# STM32G484xx register map
File version: 1.0
Registers are 32-bit, read-write, reset 0x0 unless marked. A register's access mark holds for its fields unless they carry their own. Offsets are from the block's base; [hi:lo] are bit positions.

## DAC — Digital to Analog Converter
Base 0x50000800
Same registers: DAC1 0x50000800 (alternate view of DAC), DAC2 0x50000C00, DAC3 0x50001000, DAC4 0x50001400
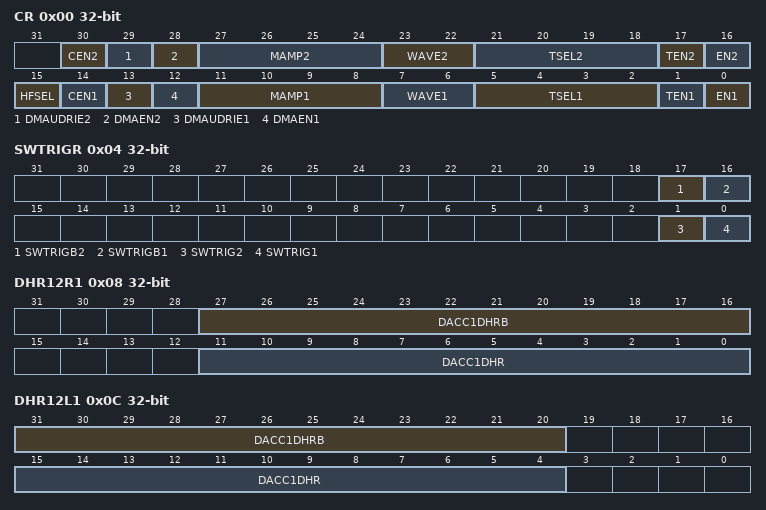
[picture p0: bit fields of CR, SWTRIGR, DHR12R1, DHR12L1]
0x00 CR — DAC control register
  [30] CEN2 — DAC channel2 calibration enable >
  [29] DMAUDRIE2 — DAC channel2 DMA underrun interrupt enable >
  [28] DMAEN2 — DAC channel2 DMA enabled
  [27:24] MAMP2 — MAMP2[3:0] (DAC channel2 Mask/Amplitude selector)
  [23:22] WAVE2 — WAVE2[1:0] (DAC channel2 noise/triangle wave generation enable)
  [21:18] TSEL2 — TSEL2[3:0] (DAC channel2 Trigger selection)
  [17] TEN2 — DAC channel2 Trigger enable
  [16] EN2 — DAC channel2 enable
  [15] HFSEL — DAC channel 1 and 2 high frequency mode enable >
  [14] CEN1 — DAC channel 1 calibration enable >
  [13] DMAUDRIE1 — DAC channel 1 DMA underrun interrupt enable >
  [12] DMAEN1 — DAC channel1 DMA enable
  [11:8] MAMP1 — MAMP1[3:0] (DAC channel1 Mask/Amplitude selector)
  [7:6] WAVE1 — WAVE1[1:0] (DAC channel1 noise/triangle wave generation enable)
  [5:2] TSEL1 — TSEL1[3:0] (DAC channel1 Trigger selection)
  [1] TEN1 — DAC channel1 Trigger enable
  [0] EN1 — DAC channel1 enable
0x04 SWTRIGR — DAC software trigger register
  [17] SWTRIGB2 — DAC channel2 software trigger B
  [16] SWTRIGB1 — DAC channel1 software trigger B
  [1] SWTRIG2 — DAC channel2 software trigger
  [0] SWTRIG1 — DAC channel1 software trigger
0x08 DHR12R1 — DAC channel1 12-bit right-aligned data holding register
  [27:16] DACC1DHRB — DAC channel1 12-bit Right-aligned data B
  [11:0] DACC1DHR — DAC channel1 12-bit Right aligned data
0x0C DHR12L1 — DAC channel1 12-bit left aligned data holding register
  [31:20] DACC1DHRB — DAC channel1 12-bit Left aligned data B
  [15:4] DACC1DHR — DAC channel1 12-bit Left aligned data
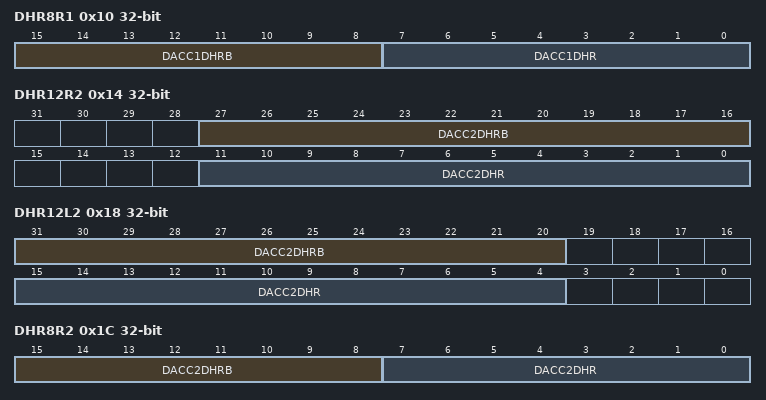
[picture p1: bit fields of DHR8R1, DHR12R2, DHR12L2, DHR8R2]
0x10 DHR8R1 — DAC channel1 8-bit right aligned data holding register
  [15:8] DACC1DHRB — DAC channel1 8-bit Right aligned data B
  [7:0] DACC1DHR — DAC channel1 8-bit Right aligned data
0x14 DHR12R2 — DAC channel2 12-bit right aligned data holding register
  [27:16] DACC2DHRB — DAC channel2 12-bit Right-aligned data B
  [11:0] DACC2DHR — DAC channel2 12-bit Right aligned data
0x18 DHR12L2 — DAC channel2 12-bit left aligned data holding register
  [31:20] DACC2DHRB — DAC channel2 12-bit Left aligned data B
  [15:4] DACC2DHR — DAC channel2 12-bit Left aligned data
0x1C DHR8R2 — DAC channel2 8-bit right-aligned data holding register
  [15:8] DACC2DHRB — DAC channel2 8-bit Right aligned data B
  [7:0] DACC2DHR — DAC channel2 8-bit Right aligned data
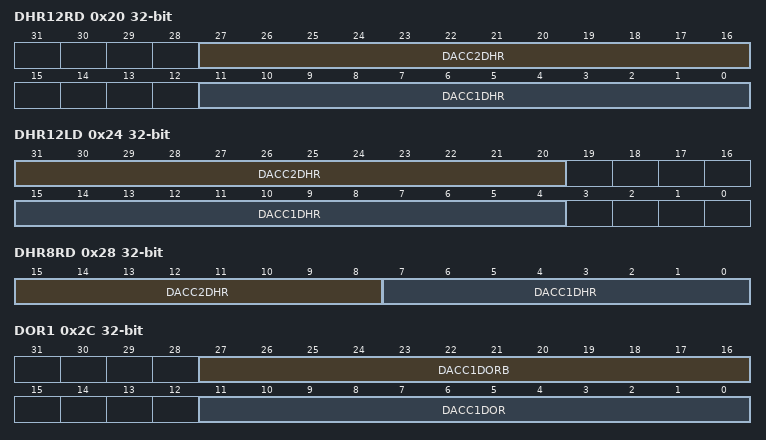
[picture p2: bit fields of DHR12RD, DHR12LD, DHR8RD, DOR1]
0x20 DHR12RD — Dual DAC 12-bit right-aligned data holding register
  [27:16] DACC2DHR — DAC channel2 12-bit Right aligned data
  [11:0] DACC1DHR — DAC channel1 12-bit Right aligned data
0x24 DHR12LD — DUAL DAC 12-bit left aligned data holding register
  [31:20] DACC2DHR — DAC channel2 12-bit Left aligned data
  [15:4] DACC1DHR — DAC channel1 12-bit Left aligned data
0x28 DHR8RD — DUAL DAC 8-bit right aligned data holding register
  [15:8] DACC2DHR — DAC channel2 8-bit Right aligned data
  [7:0] DACC1DHR — DAC channel1 8-bit Right aligned data
0x2C DOR1 — DAC channel1 data output register
  [27:16] DACC1DORB — DAC channel1 data output B
  [11:0] DACC1DOR — DAC channel1 data output
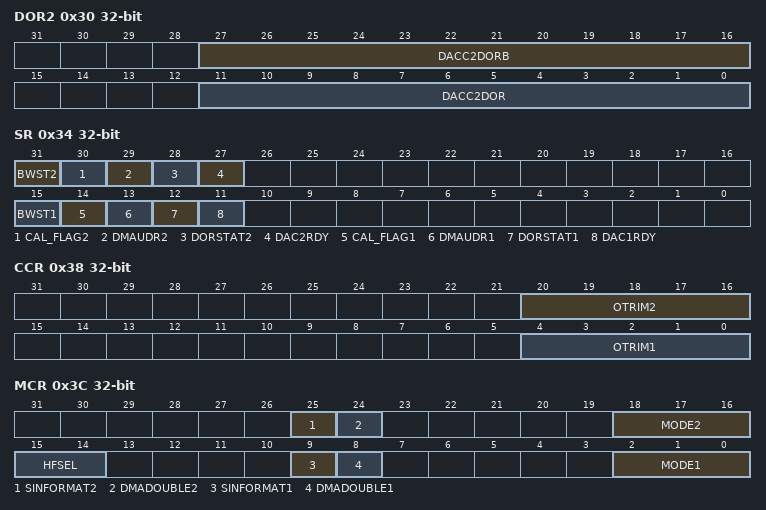
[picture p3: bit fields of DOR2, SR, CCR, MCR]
0x30 DOR2 — DAC channel2 data output register
  [27:16] DACC2DORB — DAC channel2 data output B
  [11:0] DACC2DOR — DAC channel2 data output
0x34 SR — DAC status register
  [31] BWST2 — DAC channel2 busy writing sample time flag
  [30] CAL_FLAG2 — DAC channel2 calibration offset status
  [29] DMAUDR2 — DAC channel2 DMA underrun flag
  [28] DORSTAT2 — DAC channel 2 output register status bit
  [27] DAC2RDY — DAC channel 2 ready status bit
  [15] BWST1 — DAC channel1 busy writing sample time flag
  [14] CAL_FLAG1 — DAC channel1 calibration offset status
  [13] DMAUDR1 — DAC channel1 DMA underrun flag
  [12] DORSTAT1 — DAC channel 1 output register status bit
  [11] DAC1RDY — DAC channel 1 ready status bit
0x38 CCR — DAC calibration control register
  [20:16] OTRIM2 — DAC channel2 offset trimming value
  [4:0] OTRIM1 — DAC channel1 offset trimming value
0x3C MCR — DAC mode control register
  [25] SINFORMAT2 — DAC Channel 2 enable signed format
  [24] DMADOUBLE2 — DAC Channel 2 DMA double data mode
  [18:16] MODE2 — MODE2[2:0] (DAC channel2 mode)
  [15:14] HFSEL — HFSEL[1:0] (High Frequency interface mode selection)
    0=DISABLE (High frequency interface mode disabled); 1=ABOVE_80MHZ (High frequency interface mode compatible to AHB>80MHz enabled); 2=ABOVE_160MHZ (High frequency interface mode compatible to AHB>160MHz enabled)
  [9] SINFORMAT1 — DAC Channel 1 enable signed format
  [8] DMADOUBLE1 — DAC Channel 1 DMA double data mode
  [2:0] MODE1 — MODE1[2:0] (DAC channel1 mode)
0x40 SHSR1 — DAC Sample and Hold sample time register 1
  [9:0] TSAMPLE1 — DAC channel1 sample time
0x44 SHSR2 — DAC Sample and Hold sample time register 2
  [9:0] TSAMPLE2 — DAC channel2 sample time
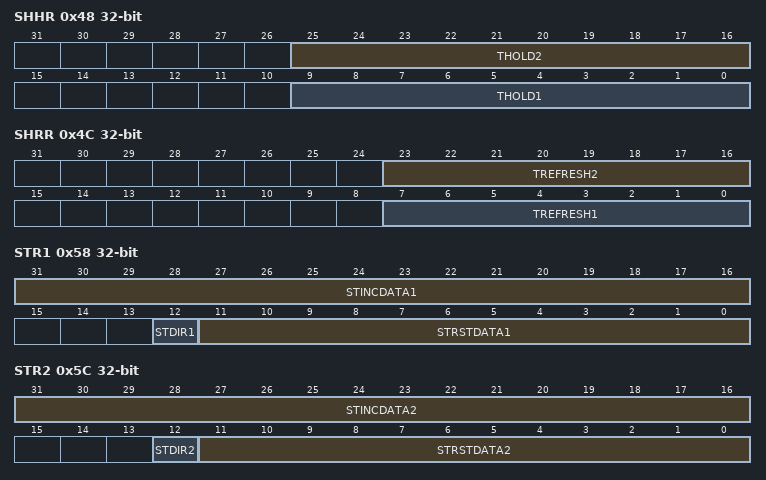
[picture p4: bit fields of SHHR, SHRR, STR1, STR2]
0x48 SHHR — DAC Sample and Hold hold time register
  [25:16] THOLD2 — DAC channel2 hold time
  [9:0] THOLD1 — DAC channel1 hold time
0x4C SHRR — DAC Sample and Hold refresh time register
  [23:16] TREFRESH2 — DAC channel2 refresh time
  [7:0] TREFRESH1 — DAC channel1 refresh time
0x58 STR1 — DAC Sawtooth register
  [31:16] STINCDATA1 — DAC Channel 1 Sawtooth increment value (12.4 bit format)
  [12] STDIR1 — DAC Channel 1 Sawtooth direction setting
  [11:0] STRSTDATA1 — DAC Channel 1 Sawtooth starting value
0x5C STR2 — DAC Sawtooth register
  [31:16] STINCDATA2 — DAC Channel 2 Sawtooth increment value (12.4 bit format)
  [12] STDIR2 — DAC Channel 2 Sawtooth direction setting
  [11:0] STRSTDATA2 — DAC Channel 2 Sawtooth starting value
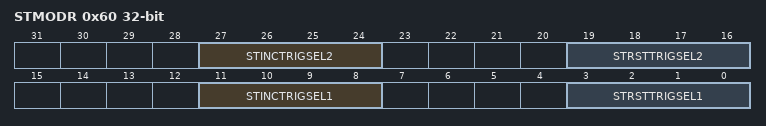
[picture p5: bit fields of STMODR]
0x60 STMODR — DAC Sawtooth Mode register
  [27:24] STINCTRIGSEL2 — STINCTRIGSEL2[3:0] (DAC Channel 2 Sawtooth Increment trigger selection)
  [19:16] STRSTTRIGSEL2 — STRSTTRIGSEL2[3:0] (DAC Channel 2 Sawtooth Increment trigger selection)
  [11:8] STINCTRIGSEL1 — STINCTRIGSEL1[3:0] (DAC Channel 1 Sawtooth Increment trigger selection)
  [3:0] STRSTTRIGSEL1 — STRSTTRIGSEL1[3:0] (DAC Channel 1 Sawtooth Increment trigger selection)
